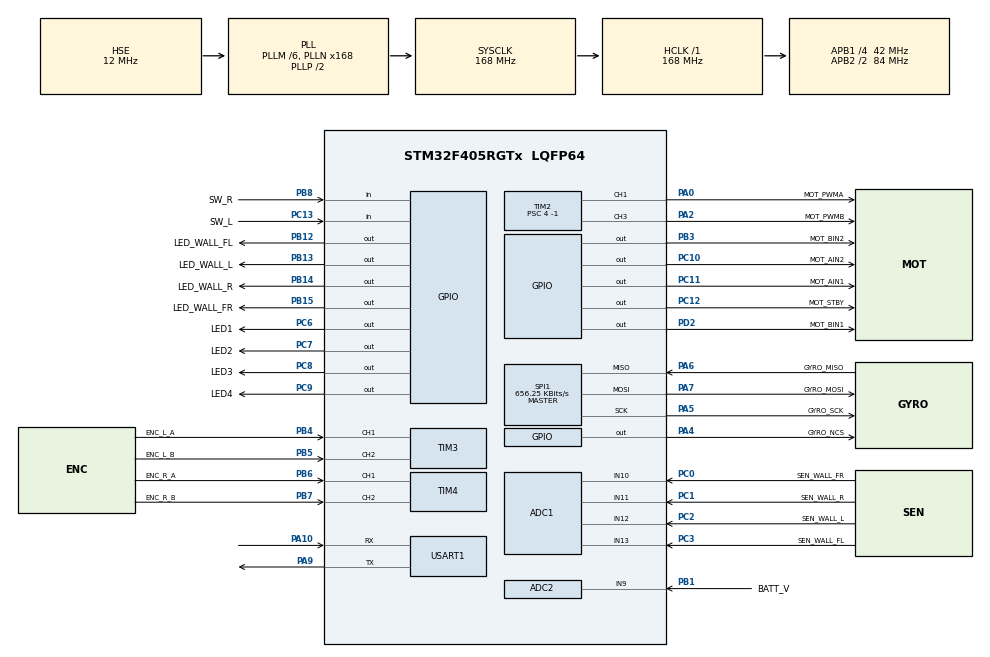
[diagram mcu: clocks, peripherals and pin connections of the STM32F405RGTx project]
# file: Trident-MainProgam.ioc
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ADC1.Channel-0\#ChannelRegularConversion=ADC_CHANNEL_10
ADC1.Channel-1\#ChannelRegularConversion=ADC_CHANNEL_11
ADC1.Channel-2\#ChannelRegularConversion=ADC_CHANNEL_12
ADC1.Channel-3\#ChannelRegularConversion=ADC_CHANNEL_13
ADC1.ClockPrescaler=ADC_CLOCK_SYNC_PCLK_DIV6
ADC1.ContinuousConvMode=ENABLE
ADC1.DMAContinuousRequests=ENABLE
ADC1.DiscontinuousConvMode=DISABLE
ADC1.EOCSelection=ADC_EOC_SEQ_CONV
ADC1.NbrOfConversion=4
ADC1.NbrOfConversionFlag=1
ADC1.Rank-0\#ChannelRegularConversion=1
ADC1.Rank-1\#ChannelRegularConversion=2
ADC1.Rank-2\#ChannelRegularConversion=3
ADC1.Rank-3\#ChannelRegularConversion=4
ADC1.SamplingTime-0\#ChannelRegularConversion=ADC_SAMPLETIME_15CYCLES
ADC1.SamplingTime-1\#ChannelRegularConversion=ADC_SAMPLETIME_15CYCLES
ADC1.SamplingTime-2\#ChannelRegularConversion=ADC_SAMPLETIME_15CYCLES
ADC1.SamplingTime-3\#ChannelRegularConversion=ADC_SAMPLETIME_15CYCLES
ADC1.master=1
ADC2.Channel-0\#ChannelRegularConversion=ADC_CHANNEL_9
ADC2.ClockPrescaler=ADC_CLOCK_SYNC_PCLK_DIV6
ADC2.NbrOfConversionFlag=1
ADC2.Rank-0\#ChannelRegularConversion=1
ADC2.SamplingTime-0\#ChannelRegularConversion=ADC_SAMPLETIME_15CYCLES
Dma.ADC1.0.Direction=DMA_PERIPH_TO_MEMORY
Dma.ADC1.0.FIFOMode=DMA_FIFOMODE_DISABLE
Dma.ADC1.0.Instance=DMA2_Stream0
Dma.ADC1.0.MemDataAlignment=DMA_MDATAALIGN_HALFWORD
Dma.ADC1.0.MemInc=DMA_MINC_ENABLE
Dma.ADC1.0.Mode=DMA_CIRCULAR
Dma.ADC1.0.PeriphDataAlignment=DMA_PDATAALIGN_HALFWORD
Dma.ADC1.0.PeriphInc=DMA_PINC_DISABLE
Dma.ADC1.0.Priority=DMA_PRIORITY_LOW
Dma.Request0=ADC1
Mcu.Family=STM32F4
Mcu.Name=STM32F405RGTx
Mcu.Package=LQFP64
NVIC.DMA2_Stream0_IRQn=true\:0\:0\:false\:false\:true\:false\:true\:true
NVIC.PriorityGroup=NVIC_PRIORITYGROUP_4
NVIC.TIM5_IRQn=true\:0\:0\:false\:false\:true\:true\:true\:true
NVIC.TIM6_DAC_IRQn=true\:0\:0\:false\:false\:true\:true\:true\:true
NVIC.TIM7_IRQn=true\:0\:0\:false\:false\:true\:true\:true\:true
NVIC.TIM8_BRK_TIM12_IRQn=true\:0\:0\:false\:false\:true\:true\:true\:true
PA0-WKUP.GPIO_Label=MOT_PWMA
PA0-WKUP.Signal=S_TIM2_CH1_ETR
PA10.Mode=Asynchronous
PA10.Signal=USART1_RX
PA13.Mode=Serial_Wire
PA13.Signal=SYS_JTMS-SWDIO
PA14.Mode=Serial_Wire
PA14.Signal=SYS_JTCK-SWCLK
PA2.GPIO_Label=MOT_PWMB
PA2.Signal=S_TIM2_CH3
PA4.GPIO_Label=GYRO_NCS
PA4.Signal=GPIO_Output
PA5.GPIO_Label=GYRO_SCK
PA5.Mode=Full_Duplex_Master
PA5.Signal=SPI1_SCK
PA6.GPIO_Label=GYRO_MISO
PA6.Mode=Full_Duplex_Master
PA6.Signal=SPI1_MISO
PA7.GPIO_Label=GYRO_MOSI
PA7.Mode=Full_Duplex_Master
PA7.Signal=SPI1_MOSI
PA9.Mode=Asynchronous
PA9.Signal=USART1_TX
PB1.GPIO_Label=BATT_V
PB1.Signal=ADCx_IN9
PB12.GPIO_Label=LED_WALL_FL
PB12.Signal=GPIO_Output
PB13.GPIO_Label=LED_WALL_L
PB13.Signal=GPIO_Output
PB14.GPIO_Label=LED_WALL_R
PB14.Signal=GPIO_Output
PB15.GPIO_Label=LED_WALL_FR
PB15.Signal=GPIO_Output
PB3.GPIO_Label=MOT_BIN2
PB3.Signal=GPIO_Output
PB4.GPIO_Label=ENC_L_A
PB4.Signal=S_TIM3_CH1
PB5.GPIO_Label=ENC_L_B
PB5.Signal=S_TIM3_CH2
PB6.GPIO_Label=ENC_R_A
PB6.Signal=S_TIM4_CH1
PB7.GPIO_Label=ENC_R_B
PB7.Signal=S_TIM4_CH2
PB8.GPIO_Label=SW_R
PB8.GPIO_PuPd=GPIO_PULLUP
PB8.Signal=GPIO_Input
PB9.GPIO_Label=BUZZER
PB9.Signal=S_TIM11_CH1
PC0.GPIO_Label=SEN_WALL_FR
PC0.Signal=ADCx_IN10
PC1.GPIO_Label=SEN_WALL_R
PC1.Signal=ADCx_IN11
PC10.GPIO_Label=MOT_AIN2
PC10.Signal=GPIO_Output
PC11.GPIO_Label=MOT_AIN1
PC11.Signal=GPIO_Output
PC12.GPIO_Label=MOT_STBY
PC12.Signal=GPIO_Output
PC13-ANTI_TAMP.GPIO_Label=SW_L
PC13-ANTI_TAMP.GPIO_PuPd=GPIO_PULLUP
PC13-ANTI_TAMP.Signal=GPIO_Input
PC2.GPIO_Label=SEN_WALL_L
PC2.Signal=ADCx_IN12
PC3.GPIO_Label=SEN_WALL_FL
PC3.Signal=ADCx_IN13
PC6.GPIO_Label=LED1
PC6.PinState=GPIO_PIN_SET
PC6.Signal=GPIO_Output
PC7.GPIO_Label=LED2
PC7.PinState=GPIO_PIN_SET
PC7.Signal=GPIO_Output
PC8.GPIO_Label=LED3
PC8.PinState=GPIO_PIN_SET
PC8.Signal=GPIO_Output
PC9.GPIO_Label=LED4
PC9.PinState=GPIO_PIN_SET
PC9.Signal=GPIO_Output
PD2.GPIO_Label=MOT_BIN1
PD2.Signal=GPIO_Output
PH0-OSC_IN.Mode=HSE-External-Oscillator
PH0-OSC_IN.Signal=RCC_OSC_IN
PH1-OSC_OUT.Mode=HSE-External-Oscillator
PH1-OSC_OUT.Signal=RCC_OSC_OUT
ProjectManager.HeapSize=0x200
ProjectManager.StackSize=0x400
ProjectManager.TargetToolchain=STM32CubeIDE
RCC.48MHZClocksFreq_Value=84000000
RCC.AHBFreq_Value=168000000
RCC.APB1CLKDivider=RCC_HCLK_DIV4
RCC.APB1Freq_Value=42000000
RCC.APB1TimFreq_Value=84000000
RCC.APB2CLKDivider=RCC_HCLK_DIV2
RCC.APB2Freq_Value=84000000
RCC.APB2TimFreq_Value=168000000
RCC.CortexFreq_Value=168000000
RCC.HCLKFreq_Value=168000000
RCC.HSE_VALUE=12000000
RCC.HSI_VALUE=16000000
RCC.LSE_VALUE=32768
RCC.PLLM=6
RCC.PLLN=168
RCC.PLLSourceVirtual=RCC_PLLSOURCE_HSE
RCC.SYSCLKFreq_VALUE=168000000
RCC.SYSCLKSource=RCC_SYSCLKSOURCE_PLLCLK
RCC.VCOOutputFreq_Value=336000000
SH.ADCx_IN10.0=ADC1_IN10,IN10
SH.ADCx_IN11.0=ADC1_IN11,IN11
SH.ADCx_IN12.0=ADC1_IN12,IN12
SH.ADCx_IN13.0=ADC1_IN13,IN13
SH.ADCx_IN9.0=ADC2_IN9,IN9
SH.S_TIM11_CH1.0=TIM11_CH1
SH.S_TIM2_CH1_ETR.0=TIM2_CH1,PWM Generation1 CH1
SH.S_TIM2_CH3.0=TIM2_CH3,PWM Generation3 CH3
SH.S_TIM3_CH1.0=TIM3_CH1,Encoder_Interface
SH.S_TIM3_CH2.0=TIM3_CH2,Encoder_Interface
SH.S_TIM4_CH1.0=TIM4_CH1,Encoder_Interface
SH.S_TIM4_CH2.0=TIM4_CH2,Encoder_Interface
SPI1.BaudRatePrescaler=SPI_BAUDRATEPRESCALER_128
SPI1.CLKPhase=SPI_PHASE_2EDGE
SPI1.CLKPolarity=SPI_POLARITY_HIGH
SPI1.CalculateBaudRate=656.25 KBits/s
SPI1.Direction=SPI_DIRECTION_2LINES
SPI1.Mode=SPI_MODE_MASTER
SPI1.VirtualType=VM_MASTER
TIM12.Period=100 - 1
TIM12.Prescaler=840 - 1
TIM2.Channel-PWM\ Generation1\ CH1=TIM_CHANNEL_1
TIM2.Channel-PWM\ Generation3\ CH3=TIM_CHANNEL_3
TIM2.Period=1000 -1 
TIM2.Prescaler=4 -1
TIM3.EncoderMode=TIM_ENCODERMODE_TI12
TIM4.EncoderMode=TIM_ENCODERMODE_TI12
TIM5.Period=100 - 1
TIM5.Prescaler=840 - 1
TIM6.Period=100 - 1
TIM6.Prescaler=840 - 1
TIM7.Period=100 - 1
TIM7.Prescaler=840 - 1
USART1.VirtualMode=VM_ASYNC
VP_TIM11_VS_ClockSourceINT.Mode=Enable_Timer
VP_TIM12_VS_ClockSourceINT.Mode=Internal
VP_TIM2_VS_ClockSourceINT.Mode=Internal
VP_TIM5_VS_ClockSourceINT.Mode=Internal
VP_TIM6_VS_ClockSourceINT.Mode=Enable_Timer
VP_TIM7_VS_ClockSourceINT.Mode=Enable_Timer
board=custom

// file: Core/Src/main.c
/* USER CODE BEGIN Header */
/**
  ******************************************************************************
  * @file           : main.c
  * @brief          : Main program body
  ******************************************************************************
  * @attention
  *
  * Copyright (c) 2023 STMicroelectronics.
  * All rights reserved.
  *
  * This software is licensed under terms that can be found in the LICENSE file
  * in the root directory of this software component.
  * If no LICENSE file comes with this software, it is provided AS-IS.
  *
  ******************************************************************************
  */
/* USER CODE END Header */
#include "main.h"
#include "adc.h"
#include "dma.h"
#include "spi.h"
#include "tim.h"
#include "usart.h"
#include "gpio.h"

void SystemClock_Config(void);

int main(void)
{

  /* MCU Configuration--------------------------------------------------------*/

  /* Reset of all peripherals, Initializes the Flash interface and the Systick. */
  HAL_Init();

  /* Configure the system clock */
  SystemClock_Config();

  /* Initialize all configured peripherals */
  MX_GPIO_Init();
  MX_DMA_Init();
  MX_USART1_UART_Init();
  MX_TIM5_Init();
  MX_ADC2_Init();
  MX_ADC1_Init();
  MX_SPI1_Init();
  MX_TIM3_Init();
  MX_TIM4_Init();
  MX_TIM2_Init();
  MX_TIM12_Init();
  MX_TIM6_Init();
  MX_TIM7_Init();
  MX_TIM11_Init();

  /* Infinite loop */
  /* USER CODE BEGIN WHILE */
  System_Init();
  while (1)
  {
    /* USER CODE END WHILE */

    /* USER CODE BEGIN 3 */
	  System_Loop();
  }
  /* USER CODE END 3 */
}

void SystemClock_Config(void)
{
  RCC_OscInitTypeDef RCC_OscInitStruct = {0};
  RCC_ClkInitTypeDef RCC_ClkInitStruct = {0};

  /** Configure the main internal regulator output voltage
  */
  __HAL_RCC_PWR_CLK_ENABLE();
  __HAL_PWR_VOLTAGESCALING_CONFIG(PWR_REGULATOR_VOLTAGE_SCALE1);

  /** Initializes the RCC Oscillators according to the specified parameters
  * in the RCC_OscInitTypeDef structure.
  */
  RCC_OscInitStruct.OscillatorType = RCC_OSCILLATORTYPE_HSE;
  RCC_OscInitStruct.HSEState = RCC_HSE_ON;
  RCC_OscInitStruct.PLL.PLLState = RCC_PLL_ON;
  RCC_OscInitStruct.PLL.PLLSource = RCC_PLLSOURCE_HSE;
  RCC_OscInitStruct.PLL.PLLM = 6;
  RCC_OscInitStruct.PLL.PLLN = 168;
  RCC_OscInitStruct.PLL.PLLP = RCC_PLLP_DIV2;
  RCC_OscInitStruct.PLL.PLLQ = 4;
  if (HAL_RCC_OscConfig(&RCC_OscInitStruct) != HAL_OK)
  {
    Error_Handler();
  }

  /** Initializes the CPU, AHB and APB buses clocks
  */
  RCC_ClkInitStruct.ClockType = RCC_CLOCKTYPE_HCLK|RCC_CLOCKTYPE_SYSCLK
                              |RCC_CLOCKTYPE_PCLK1|RCC_CLOCKTYPE_PCLK2;
  RCC_ClkInitStruct.SYSCLKSource = RCC_SYSCLKSOURCE_PLLCLK;
  RCC_ClkInitStruct.AHBCLKDivider = RCC_SYSCLK_DIV1;
  RCC_ClkInitStruct.APB1CLKDivider = RCC_HCLK_DIV4;
  RCC_ClkInitStruct.APB2CLKDivider = RCC_HCLK_DIV2;

  if (HAL_RCC_ClockConfig(&RCC_ClkInitStruct, FLASH_LATENCY_5) != HAL_OK)
  {
    Error_Handler();
  }
}

void Error_Handler(void)
{
  __disable_irq();
  while (1)
  {
  }
}
